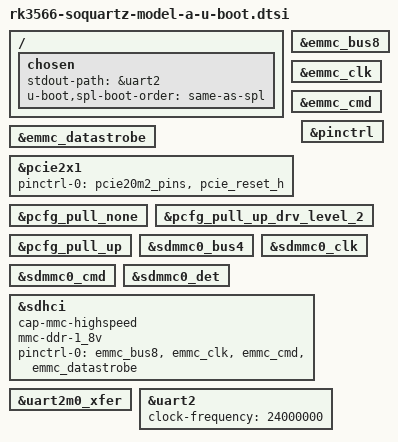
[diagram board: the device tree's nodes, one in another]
// SPDX-License-Identifier: GPL-2.0+
/*
 * (C) Copyright 2021 Rockchip Electronics Co., Ltd
 */

#include "rk356x-u-boot.dtsi"

/ {
	chosen {
		stdout-path = &uart2;
		u-boot,spl-boot-order = "same-as-spl", &sdmmc0, &sdhci;
	};
};

&emmc_bus8 {
	bootph-all;
};

&emmc_clk {
	bootph-all;
};

&emmc_cmd {
	bootph-all;
};

&emmc_datastrobe {
	bootph-all;
};

&pcie2x1 {
	pinctrl-0 = <&pcie20m2_pins &pcie_reset_h>;
};

&pinctrl {
	bootph-all;
};

&pcfg_pull_none {
	bootph-all;
};

&pcfg_pull_up_drv_level_2 {
	bootph-all;
};

&pcfg_pull_up {
	bootph-all;
};

&sdmmc0_bus4 {
	bootph-all;
};

&sdmmc0_clk {
	bootph-all;
};

&sdmmc0_cmd {
	bootph-all;
};

&sdmmc0_det {
	bootph-all;
};

&sdhci {
	cap-mmc-highspeed;
	mmc-ddr-1_8v;
	pinctrl-names = "default";
	pinctrl-0 = <&emmc_bus8 &emmc_clk &emmc_cmd &emmc_datastrobe>;
};

&uart2m0_xfer {
	bootph-all;
};

&uart2 {
	clock-frequency = <24000000>;
	bootph-all;
	status = "okay";
};
